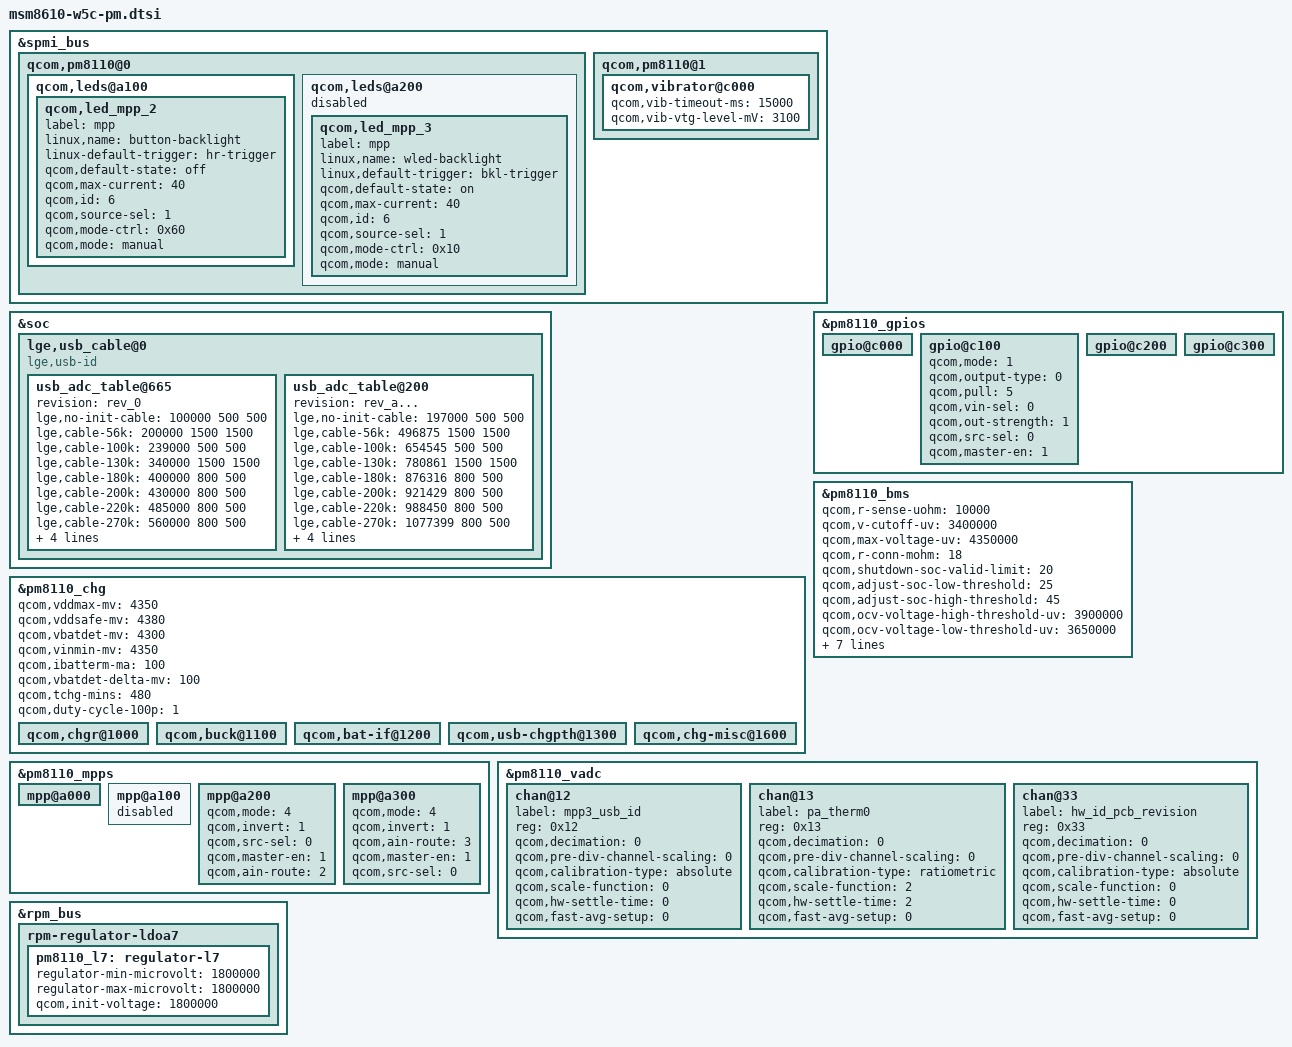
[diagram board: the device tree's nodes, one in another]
/* Copyright (c) 2012, Code Aurora Forum. All rights reserved.
 *
 * This program is free software; you can redistribute it and/or modify
* it under the terms of the GNU General Public License version 2 and
* only version 2 as published by the Free Software Foundation.
*
* This program is distributed in the hope that it will be useful,
* but WITHOUT ANY WARRANTY; without even the implied warranty of
* MERCHANTABILITY or FITNESS FOR A PARTICULAR PURPOSE.  See the
* GNU General Public License for more details.
*/

/ {

};

&spmi_bus {
	qcom,pm8110@0 {
		qcom,leds@a100 {
			status = "okay";
			qcom,led_mpp_2 {
				label = "mpp";
				linux,name = "button-backlight";
				linux-default-trigger = "hr-trigger";
				qcom,default-state = "off";
				qcom,max-current = <40>;
				qcom,id = <6>;
				qcom,source-sel = <1>;
				qcom,mode-ctrl = <0x60>;
				qcom,mode = "manual";
			};
		};

		qcom,leds@a200 {
			status = "disabled";
			qcom,led_mpp_3 {
				label = "mpp";
				linux,name = "wled-backlight";
				linux,default-trigger = "bkl-trigger";
				qcom,default-state = "on";
				qcom,max-current = <40>;
				qcom,id = <6>;
				qcom,source-sel = <1>;
				qcom,mode-ctrl = <0x10>;
				qcom,mode = "manual";
			};
		};
	};
};

&spmi_bus {
	qcom,pm8110@1 {
		qcom,vibrator@c000 {
			status = "okay";
			qcom,vib-timeout-ms = <15000>;
			qcom,vib-vtg-level-mV = <3100>;
		};
	};
};

&soc{
	/* Cable type definition.
	* Modify the USB cable and move to SoC
	* to get each table for different USB Pull up resistor via HW Rev
	* This must have the compatible property "lge,usb-id".
	* If you don't want to use revision you can remove status & revision property.
	* If this node is not exist, the charger driver would not be probed.
	* Each cable type has 3 values
	* that we can configure the threshold of ADC value and TA/USB IUSB max current value.
	* ex)
	*    cable type = <adc_threshold, TA_MA, USB_MA>.
	*/

	lge,usb_cable@0 {
		compatible = "lge,usb-id";
		usb_adc_table@665{
			status = "okay";
			revision = "rev_0";
			lge,no-init-cable = <100000 500 500>;
			lge,cable-56k = <200000 1500 1500>;
			lge,cable-100k = <239000 500 500>;
			lge,cable-130k = <340000 1500 1500>;
			lge,cable-180k = <400000 800 500>;
			lge,cable-200k = <430000 800 500>;
			lge,cable-220k = <485000 800 500>;
			lge,cable-270k = <560000 800 500>;
			lge,cable-330k = <735000 500 500>;
			lge,cable-620k = <955000 500 500>;
			lge,cable-910k = <1140000 1500 1500>;
			lge,cable-none = <1900000 800  500>;
		};
		usb_adc_table@200{
			status = "okay";
			revision = "rev_a...";
			lge,no-init-cable = <197000 500 500>;
			lge,cable-56k = <496875 1500 1500>;
			lge,cable-100k = <654545 500 500>;
			lge,cable-130k = <780861 1500 1500>;
			lge,cable-180k = <876316 800 500>;
			lge,cable-200k = <921429 800 500>;
			lge,cable-220k = <988450 800 500>;
			lge,cable-270k = <1077399 800 500>;
			lge,cable-330k = <1240865 500 500>;
			lge,cable-620k = <1418326 500 500>;
			lge,cable-910k = <1637838 1500 1500>;
			lge,cable-none = <1900000 800  500>;
		};
	};
};

&pm8110_chg {
	status = "ok";
	qcom,vddmax-mv = <4350>;
	qcom,vddsafe-mv = <4380>;
	qcom,vbatdet-mv = <4300>;
	qcom,vinmin-mv = <4350>;
	qcom,ibatterm-ma = <100>;
	qcom,vbatdet-delta-mv = <100>;
	qcom,tchg-mins = <480>;
	qcom,duty-cycle-100p = <1>;

	qcom,chgr@1000 {
		status = "ok";
	};

	qcom,buck@1100 {
		status = "ok";
	};

	qcom,bat-if@1200 {
		status = "ok";
	};

	qcom,usb-chgpth@1300 {
		status = "ok";
	};

	qcom,chg-misc@1600 {
		status = "ok";
	};
};

&pm8110_gpios {
	gpio@c000 { /* GPIO 1 */		/* NFC_CLK_REQ */
	};

	gpio@c100 { /* GPIO 2 */		/* TX_GTR_THRESH */
		qcom,mode = <1>;			/* QPNP_PIN_MODE_DIG_OUT */
		qcom,output-type = <0>;		/* QPNP_PIN_OUT_BUF_CMOS */
		qcom,pull = <5>;			/* QPNP_PIN_PULL_NO */
		qcom,vin-sel = <0>;			/* QPNP_PIN_VIN0 */
		qcom,out-strength = <1>;	/* QPNP_PIN_OUT_STRENGTH_LOW */
		qcom,src-sel = <0>;			/* QPNP_PIN_SEL_FUNC_CONSTANT */
		qcom,master-en = <1>;		/* Eable GPIO */
	};

	gpio@c200 { /* GPIO 3 */		/* NC */
	};

	gpio@c300 { /* GPIO 4 */		/* BAT_UICC_ALARM */
	};
};

&pm8110_mpps {
	mpp@a000 { /* MPP 1 */			/* VDD_PX_BIAS */
	};

	mpp@a100 { /* MPP 2 */			/* VPWR_KEY_LED */
		status = "disabled";
	};

	mpp@a200 { /* MPP 3 */			/* USB_ID */
		qcom,mode = <4>;			/* QPNP_PIN_MODE_AIN */
		qcom,invert = <1>;			/* QPNP_PIN_INVERT_ENABLE - Enable MPP */
		qcom,src-sel = <0>;			/* QPNP_PIN_SEL_FUNC_CONSTANT */
		qcom,master-en = <1>;		/* Eable GPIO */
		qcom,ain-route = <2>;		/* QPNP_PIN_AIN_AMUX_CH7 */
	};

	mpp@a300 { /* MPP 4 */			/* PA_THERM */
		/* PA_THERM config */
		qcom,mode = <4>; /* AIN input */
		qcom,invert = <1>; /* Enable MPP */
		qcom,ain-route = <3>; /* AMUX 8 */
		qcom,master-en = <1>;
		qcom,src-sel = <0>; /* Function constant */
	};
};

&pm8110_bms {
    status = "ok";

    qcom,r-sense-uohm = <10000>;
    qcom,v-cutoff-uv = <3400000>;
    qcom,max-voltage-uv = <4350000>;
    qcom,r-conn-mohm = <18>;
    qcom,shutdown-soc-valid-limit = <20>;
    qcom,adjust-soc-low-threshold = <25>;
    qcom,adjust-soc-high-threshold = <45>;
    qcom,ocv-voltage-high-threshold-uv = <3900000>;
    qcom,ocv-voltage-low-threshold-uv = <3650000>;
    qcom,low-soc-calculate-soc-threshold = <15>;
    qcom,low-soc-calculate-soc-ms = <5000>;
    qcom,calculate-soc-ms = <20000>;
    qcom,low-voltage-calculate-soc-ms=<1000>;
    qcom,chg-term-ua = <100000>;
    qcom,batt-type = <0>;
    qcom,low-voltage-threshold = <3420000>;
};

&pm8110_vadc {
	chan@12 {
		label = "mpp3_usb_id";
		reg = <0x12>;
		qcom,decimation = <0>;
		qcom,pre-div-channel-scaling = <0>;
		qcom,calibration-type = "absolute";
		qcom,scale-function = <0>;
		qcom,hw-settle-time = <0>;
		qcom,fast-avg-setup = <0>;
	};

	chan@13 {
		label = "pa_therm0";
		reg = <0x13>;
		qcom,decimation = <0>;
		qcom,pre-div-channel-scaling = <0>;
		qcom,calibration-type = "ratiometric";
		qcom,scale-function = <2>;		/* degC for 100k pull-up */
		qcom,hw-settle-time = <2>;
		qcom,fast-avg-setup = <0>;
	};

	chan@33 {
		label = "hw_id_pcb_revision";
		reg = <0x33>;
		qcom,decimation = <0>;
		qcom,pre-div-channel-scaling = <0>;
		qcom,calibration-type = "absolute";
		qcom,scale-function = <0>;
		qcom,hw-settle-time = <0>;
		qcom,fast-avg-setup = <0>;
	};

};

&rpm_bus {

	rpm-regulator-ldoa7 {
		status = "okay";
		pm8110_l7: regulator-l7 {
			regulator-min-microvolt = <1800000>;
			regulator-max-microvolt = <1800000>;
			qcom,init-voltage = <1800000>;
			status = "okay";
		};
	};
};

